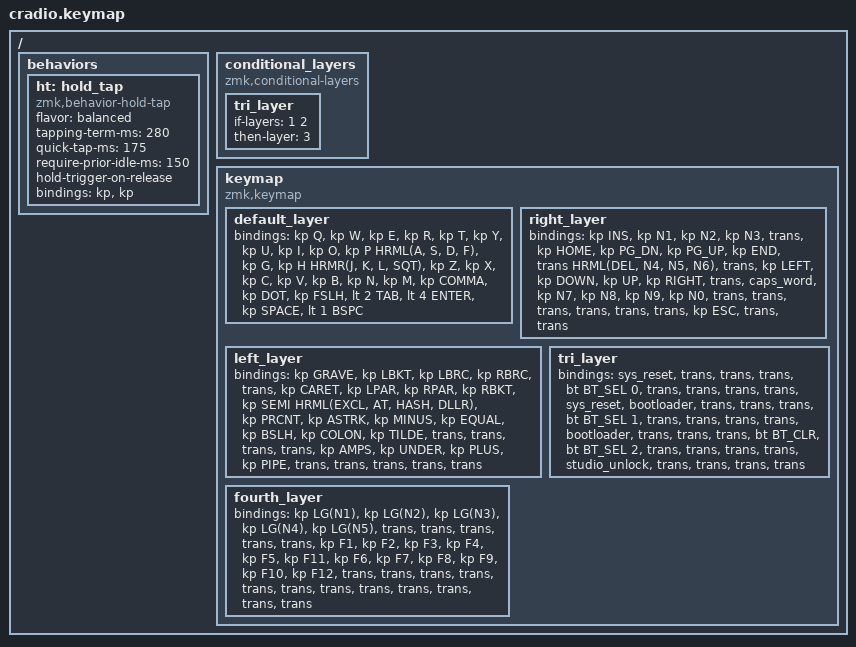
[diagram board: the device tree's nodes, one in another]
 // Copyright (c) 2022 The ZMK Contributors
// SPDX-License-Identifier: MIT

#include <behaviors.dtsi>
#include <dt-bindings/zmk/keys.h>
#include <dt-bindings/zmk/bt.h>

// Home row mods macro
#define HRML(k1,k2,k3,k4) &ht LSHFT k1  &ht LCTRL k2  &ht LALT k3  &ht LGUI k4
#define HRMR(k1,k2,k3,k4) &ht RGUI k1  &ht RALT k2  &ht RCTRL k3  &ht RSHFT k4

/ {
    behaviors {
        ht: hold_tap {
            compatible = "zmk,behavior-hold-tap";
            #binding-cells = <2>;
            flavor = "balanced";
            tapping-term-ms = <280>;
            quick-tap-ms = <175>;
            require-prior-idle-ms = <150>;
            hold-trigger-on-release;
            bindings = <&kp>, <&kp>;
        };
    };

    conditional_layers {
        compatible = "zmk,conditional-layers";
        tri_layer {
            if-layers = <1 2>;
            then-layer = <3>;
        };
    };

    keymap {
        compatible = "zmk,keymap";
        default_layer {
            bindings = <
        //╭──────────┬──────────┬──────────┬──────────┬──────────╮   ╭──────────┬──────────┬──────────┬──────────┬──────────╮
        //│  Q       │  W       │  E       │  R       │  T       │   │  Y       │  U       │  I       │  O       │  P       │
            &kp Q      &kp W      &kp E      &kp R      &kp T          &kp Y      &kp U      &kp I      &kp O      &kp P
        //├──────────┼──────────┼──────────┼──────────┼──────────┤   ├──────────┼──────────┼──────────┼──────────┼──────────┤
        //│  A       │  S       │  D       │  F       │  G       │   │  H       │  J       │  K       │  L       │ ' "      │
            HRML(A,        S,         D,         F)     &kp G          &kp H      HRMR(J,        K,         L,        SQT)
        //├──────────┼──────────┼──────────┼──────────┼──────────┤   ├──────────┼──────────┼──────────┼──────────┼──────────┤
        //│  Z       │  X       │  C       │  V       │  B       │   │  N       │  M       │ , <      │ . >      │ / ?      │
            &kp Z      &kp X      &kp C      &kp V      &kp B          &kp N      &kp M      &kp COMMA  &kp DOT    &kp FSLH
        //╰──────────┴──────────┴──────────┼──────────┼──────────┤   ├──────────┼──────────┼──────────┴──────────┴──────────╯
                                            &lt 2 TAB  &lt 4 ENTER    &kp SPACE  &lt 1 BSPC
        //                                 ╰──────────┴──────────╯   ╰──────────┴──────────╯
            >;
        };

        right_layer {
            bindings = <
        //╭──────────┬──────────┬──────────┬──────────┬──────────╮   ╭──────────┬──────────┬──────────┬──────────┬──────────╮
        //│ INSERT   │  1       │  2       │  3       │          │   │ HOME     │ PAGE DN  │ PAGE UP  │ END      │          │
            &kp INS    &kp N1     &kp N2     &kp N3     &trans         &kp HOME   &kp PG_DN  &kp PG_UP  &kp END    &trans
        //├──────────┼──────────┼──────────┼──────────┼──────────┤   ├──────────┼──────────┼──────────┼──────────┼──────────┤
        //│ DELETE   │  4       │  5       │  6       │          │   │ LEFT     │ DOWN     │ UP       │ RIGHT    │          │
            HRML(DEL,    N4,        N5,        N6)      &trans         &kp LEFT   &kp DOWN   &kp UP   &kp RIGHT    &trans
        //├──────────┼──────────┼──────────┼──────────┼──────────┤   ├──────────┼──────────┼──────────┼──────────┼──────────┤
        //│ CAPS     │  7       │  8       │  9       │  0       │   │          │          │          │          │          │
           &caps_word  &kp N7     &kp N8     &kp N9     &kp N0         &trans     &trans     &trans     &trans     &trans
        //╰──────────┴──────────┴──────────┼──────────┼──────────┤   ├──────────┼──────────┼──────────┴──────────┴──────────╯
                                             &trans     &kp ESC        &trans     &trans
        //                                 ╰──────────┴──────────╯   ╰──────────┴──────────╯
            >;
        };

        left_layer {
            bindings = <
        //╭──────────┬──────────┬──────────┬──────────┬──────────╮   ╭──────────┬──────────┬──────────┬──────────┬──────────╮
        //│    `     │  [       │  {       │  }       │          │   │  ^       │  (       │  )       │  ]       │   ;      │
           &kp GRAVE   &kp LBKT   &kp LBRC   &kp RBRC   &trans         &kp CARET  &kp LPAR   &kp RPAR   &kp RBKT   &kp SEMI
        //├──────────┼──────────┼──────────┼──────────┼──────────┤   ├──────────┼──────────┼──────────┼──────────┼──────────┤
        //│  !       │  @       │  #       │  $       │  %       │   │  *       │  -       │  =       │  \       │   :      │
            HRML(EXCL,  AT,        HASH,     DLLR)      &kp PRCNT      &kp ASTRK  &kp MINUS  &kp EQUAL  &kp BSLH   &kp COLON
        //├──────────┼──────────┼──────────┼──────────┼──────────┤   ├──────────┼──────────┼──────────┼──────────┼──────────┤
        //│  ~       │          │          │          │          │   │  &       │  _       │  +       │  │       │          │
           &kp TILDE    &trans     &trans     &trans     &trans        &kp AMPS   &kp UNDER  &kp PLUS   &kp PIPE   &trans
        //╰──────────┴──────────┴──────────┼──────────┼──────────┤   ├──────────┼──────────┼──────────┴──────────┴──────────╯
                                             &trans     &trans         &trans     &trans
        //                                 ╰──────────┴──────────╯   ╰──────────┴──────────╯
            >;
        };

        tri_layer {
            bindings = <
        //╭──────────┬──────────┬──────────┬──────────┬──────────╮   ╭──────────┬──────────┬──────────┬──────────┬──────────╮
        //│ RESET    │          │          │          │PROFILE 0 │   │          │          │          │          │  RESET   │
           &sys_reset  &trans     &trans     &trans    &bt BT_SEL 0    &trans     &trans     &trans     &trans    &sys_reset
        //├──────────┼──────────┼──────────┼──────────┼──────────┤   ├──────────┼──────────┼──────────┼──────────┼──────────┤
        //│BOOTLOADER│          │          │          │PROFILE 1 │   │          │          │          │          │BOOTLOADER│
          &bootloader  &trans     &trans     &trans    &bt BT_SEL 1    &trans     &trans     &trans     &trans    &bootloader
        //├──────────┼──────────┼──────────┼──────────┼──────────┤   ├──────────┼──────────┼──────────┼──────────┼──────────┤
        //│          │          │          │ CLEAR BT │PROFILE 2 │   │          │          │          │          │          │
            &trans     &trans     &trans    &bt BT_CLR &bt BT_SEL 2    &trans     &trans     &trans     &trans     &studio_unlock
        //╰──────────┴──────────┴──────────┼──────────┼──────────┤   ├──────────┼──────────┼──────────┴──────────┴──────────╯
                                             &trans     &trans         &trans     &trans
        //                                 ╰──────────┴──────────╯   ╰──────────┴──────────╯
            >;
        };

        fourth_layer {
            bindings = <
        //╭──────────┬──────────┬──────────┬──────────┬──────────╮   ╭──────────┬──────────┬──────────┬──────────┬──────────╮
        //│          │          │          │          │          │   │          │          │          │          │          │
           &kp LG(N1) &kp LG(N2) &kp LG(N3) &kp LG(N4) &kp LG(N5)       &trans     &trans     &trans     &trans    &trans
        //├──────────┼──────────┼──────────┼──────────┼──────────┤   ├──────────┼──────────┼──────────┼──────────┼──────────┤
        //│          │          │          │          │          │   │          │          │          │          │          │
            &kp F1     &kp F2     &kp F3     &kp F4     &kp F5         &kp F11     &kp F6     &kp F7    &kp F8      &kp F9
        //├──────────┼──────────┼──────────┼──────────┼──────────┤   ├──────────┼──────────┼──────────┼──────────┼──────────┤
        //│          │          │          │          │          │   │          │          │          │          │          │
            &kp F10     &kp F12   &trans     &trans      &trans        &trans     &trans     &trans     &trans     &trans
        //╰──────────┴──────────┴──────────┼──────────┼──────────┤   ├──────────┼──────────┼──────────┴──────────┴──────────╯
                                             &trans     &trans         &trans     &trans
        //                                 ╰──────────┴──────────╯   ╰──────────┴──────────╯
            >;
        };
    };
};
